# nrf9120_modem register map
Vendor: Nordic Semiconductor; Series: nrf91; File version: 1
CPU: CM4 r0p1, little endian, MPU, FPU, 3 interrupt priority bits
Registers are 32-bit, read-write, reset 0x0 unless marked. A register's access mark holds for its fields unless they carry their own. Offsets are from the block's base; [hi:lo] are bit positions; 'fields as' and 'values as' point back to an identical list.

## TLSAES_NS — AES cipher with ECB, CBC, CBC-MAC and CTR
Base 0x40051000
0x00 TASKS_START_GATHER wo — Start input DMA
  [0] TASKS_START_GATHER
    1=Trigger task
0x04 TASKS_STOP_GATHER wo — Stop input DMA
  [0] TASKS_STOP_GATHER
    1=Trigger task
0x08 TASKS_START_SCATTER wo — Start output DMA
  [0] TASKS_START_SCATTER
    1=Trigger task
0x0C TASKS_STOP_SCATTER wo — Stop output DMA
  [0] TASKS_STOP_SCATTER
    1=Trigger task
0x10 TASKS_INITIALIZE_AES wo — New keys (and IV) ready to be used, reset keybytes, ivbytes
  [0] TASKS_INITIALIZE_AES
    1=Trigger task
0x14 TASKS_FILL_AES_INPUT wo — Transfer 8 bytes of input from DMA to AES core
  [0] TASKS_FILL_AES_INPUT
    1=Trigger task
0x18 TASKS_AES_ENCRYPT wo — Encrypt
  [0] TASKS_AES_ENCRYPT
    1=Trigger task
0x1C TASKS_AES_DECRYPT wo — Decrypt
  [0] TASKS_AES_DECRYPT
    1=Trigger task
0x20 TASKS_DRAIN_AES_OUTPUT wo — Transfer 8 bytes of output from AES core to DMA
  [0] TASKS_DRAIN_AES_OUTPUT
    1=Trigger task
0x24 TASKS_RESET wo — Stop all transfers and crypto operations (software reset)
  [0] TASKS_RESET
    1=Trigger task
0x100 EVENTS_GATHER_STARTED — Input DMA started
  [0] EVENTS_GATHER_STARTED
    0=NotGenerated (Event not generated); 1=Generated (Event generated)
0x104 EVENTS_GATHER_DONE — Input DMA done
  [0] EVENTS_GATHER_DONE
    values as EVENTS_GATHER_STARTED.EVENTS_GATHER_STARTED
0x108 EVENTS_SCATTER_STARTED — Output DMA started
  [0] EVENTS_SCATTER_STARTED
    values as EVENTS_GATHER_STARTED.EVENTS_GATHER_STARTED
0x10C EVENTS_SCATTER_DONE — Output DMA done
  [0] EVENTS_SCATTER_DONE
    values as EVENTS_GATHER_STARTED.EVENTS_GATHER_STARTED
0x110 EVENTS_KEY_READY — Key received (keybytes == 16)
  [0] EVENTS_KEY_READY
    values as EVENTS_GATHER_STARTED.EVENTS_GATHER_STARTED
0x114 EVENTS_IV_READY — IV received (ivbytes == 16)
  [0] EVENTS_IV_READY
    values as EVENTS_GATHER_STARTED.EVENTS_GATHER_STARTED
0x118 EVENTS_AES_INITIALIZED — New keys (and IV) taken into use
  [0] EVENTS_AES_INITIALIZED
    values as EVENTS_GATHER_STARTED.EVENTS_GATHER_STARTED
0x11C EVENTS_AES_INPUT_FULL — 8 bytes of input stored to AES core
  [0] EVENTS_AES_INPUT_FULL
    values as EVENTS_GATHER_STARTED.EVENTS_GATHER_STARTED
0x120 EVENTS_AES_DONE — Encrypt/decrypt action ready
  [0] EVENTS_AES_DONE
    values as EVENTS_GATHER_STARTED.EVENTS_GATHER_STARTED
0x124 EVENTS_AES_OUTPUT_EMPTY — 8 bytes of output read from AES core
  [0] EVENTS_AES_OUTPUT_EMPTY
    values as EVENTS_GATHER_STARTED.EVENTS_GATHER_STARTED
0x128 EVENTS_MAC_READY — CBC-MAC calculated
  [0] EVENTS_MAC_READY
    values as EVENTS_GATHER_STARTED.EVENTS_GATHER_STARTED
0x12C EVENTS_RESETTED — Resetted (all transfers and crypto operations stopped)
  [0] EVENTS_RESETTED
    values as EVENTS_GATHER_STARTED.EVENTS_GATHER_STARTED
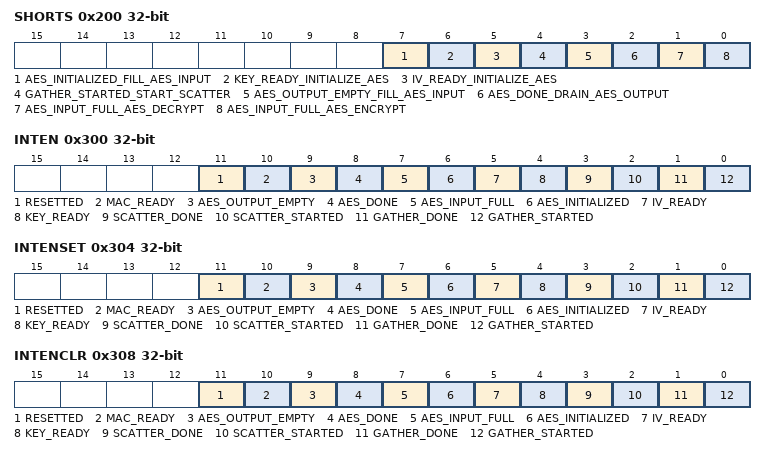
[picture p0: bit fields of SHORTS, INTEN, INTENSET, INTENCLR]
0x200 SHORTS — Shortcuts between local events and tasks
  [all] fields
    0=Disabled (Disable shortcut); 1=Enabled (Enable shortcut)
  [7] AES_INITIALIZED_FILL_AES_INPUT — Shortcut between event AES_INITIALIZED and task FILL_AES_INPUT
  [6] KEY_READY_INITIALIZE_AES — Shortcut between event KEY_READY and task INITIALIZE_AES
  [5] IV_READY_INITIALIZE_AES — Shortcut between event IV_READY and task INITIALIZE_AES
  [4] GATHER_STARTED_START_SCATTER — Shortcut between event GATHER_STARTED and task START_SCATTER
  [3] AES_OUTPUT_EMPTY_FILL_AES_INPUT — Shortcut between event AES_OUTPUT_EMPTY and task FILL_AES_INPUT
  [2] AES_DONE_DRAIN_AES_OUTPUT — Shortcut between event AES_DONE and task DRAIN_AES_OUTPUT
  [1] AES_INPUT_FULL_AES_DECRYPT — Shortcut between event AES_INPUT_FULL and task AES_DECRYPT
  [0] AES_INPUT_FULL_AES_ENCRYPT — Shortcut between event AES_INPUT_FULL and task AES_ENCRYPT
0x300 INTEN — Enable or disable interrupt
  [all] fields
    0=Disabled; 1=Enabled
  [11] RESETTED — Enable or disable interrupt for event RESETTED
  [10] MAC_READY — Enable or disable interrupt for event MAC_READY
  [9] AES_OUTPUT_EMPTY — Enable or disable interrupt for event AES_OUTPUT_EMPTY
  [8] AES_DONE — Enable or disable interrupt for event AES_DONE
  [7] AES_INPUT_FULL — Enable or disable interrupt for event AES_INPUT_FULL
  [6] AES_INITIALIZED — Enable or disable interrupt for event AES_INITIALIZED
  [5] IV_READY — Enable or disable interrupt for event IV_READY
  [4] KEY_READY — Enable or disable interrupt for event KEY_READY
  [3] SCATTER_DONE — Enable or disable interrupt for event SCATTER_DONE
  [2] SCATTER_STARTED — Enable or disable interrupt for event SCATTER_STARTED
  [1] GATHER_DONE — Enable or disable interrupt for event GATHER_DONE
  [0] GATHER_STARTED — Enable or disable interrupt for event GATHER_STARTED
0x304 INTENSET — Enable interrupt
  [all] fields
    on read: 0=Disabled (Read: Disabled); 1=Enabled (Read: Enabled) | on write: 1=Set (Enable)
  [11] RESETTED — Write '1' to enable interrupt for event RESETTED
  [10] MAC_READY — Write '1' to enable interrupt for event MAC_READY
  [9] AES_OUTPUT_EMPTY — Write '1' to enable interrupt for event AES_OUTPUT_EMPTY
  [8] AES_DONE — Write '1' to enable interrupt for event AES_DONE
  [7] AES_INPUT_FULL — Write '1' to enable interrupt for event AES_INPUT_FULL
  [6] AES_INITIALIZED — Write '1' to enable interrupt for event AES_INITIALIZED
  [5] IV_READY — Write '1' to enable interrupt for event IV_READY
  [4] KEY_READY — Write '1' to enable interrupt for event KEY_READY
  [3] SCATTER_DONE — Write '1' to enable interrupt for event SCATTER_DONE
  [2] SCATTER_STARTED — Write '1' to enable interrupt for event SCATTER_STARTED
  [1] GATHER_DONE — Write '1' to enable interrupt for event GATHER_DONE
  [0] GATHER_STARTED — Write '1' to enable interrupt for event GATHER_STARTED
0x308 INTENCLR — Disable interrupt
  [all] fields
    on read: 0=Disabled (Read: Disabled); 1=Enabled (Read: Enabled) | on write: 1=Clear (Disable)
  [11] RESETTED — Write '1' to disable interrupt for event RESETTED
  [10] MAC_READY — Write '1' to disable interrupt for event MAC_READY
  [9] AES_OUTPUT_EMPTY — Write '1' to disable interrupt for event AES_OUTPUT_EMPTY
  [8] AES_DONE — Write '1' to disable interrupt for event AES_DONE
  [7] AES_INPUT_FULL — Write '1' to disable interrupt for event AES_INPUT_FULL
  [6] AES_INITIALIZED — Write '1' to disable interrupt for event AES_INITIALIZED
  [5] IV_READY — Write '1' to disable interrupt for event IV_READY
  [4] KEY_READY — Write '1' to disable interrupt for event KEY_READY
  [3] SCATTER_DONE — Write '1' to disable interrupt for event SCATTER_DONE
  [2] SCATTER_STARTED — Write '1' to disable interrupt for event SCATTER_STARTED
  [1] GATHER_DONE — Write '1' to disable interrupt for event GATHER_DONE
  [0] GATHER_STARTED — Write '1' to disable interrupt for event GATHER_STARTED
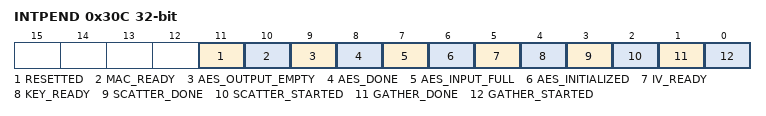
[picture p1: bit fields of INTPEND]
0x30C INTPEND ro — Pending interrupts
  [all] fields
    on read: 0=NotPending (Read: Not pending); 1=Pending (Read: Pending)
  [11] RESETTED — Read pending status of interrupt for event RESETTED
  [10] MAC_READY — Read pending status of interrupt for event MAC_READY
  [9] AES_OUTPUT_EMPTY — Read pending status of interrupt for event AES_OUTPUT_EMPTY
  [8] AES_DONE — Read pending status of interrupt for event AES_DONE
  [7] AES_INPUT_FULL — Read pending status of interrupt for event AES_INPUT_FULL
  [6] AES_INITIALIZED — Read pending status of interrupt for event AES_INITIALIZED
  [5] IV_READY — Read pending status of interrupt for event IV_READY
  [4] KEY_READY — Read pending status of interrupt for event KEY_READY
  [3] SCATTER_DONE — Read pending status of interrupt for event SCATTER_DONE
  [2] SCATTER_STARTED — Read pending status of interrupt for event SCATTER_STARTED
  [1] GATHER_DONE — Read pending status of interrupt for event GATHER_DONE
  [0] GATHER_STARTED — Read pending status of interrupt for event GATHER_STARTED
0x400 MODE — Operation mode
  [1:0] MODE — Selects ECB, CBC, CBC-MAC or CTR mode
    0=ECB (Electronic Codebook mode); 1=CBC (Cipher Block Chaining mode); 2=CBCMAC (Cipher Block Chaining Message Authentication Code mode); 3=CTR (Counter mode)
0x404 CTRBITS — Amount of counter bits used in the CTR mode
  [6:0] CTRBITS
0x408 KEYMODE — Selects which key is utilized in ciphering operations
  [1:0] KEYMODE — Keying mode
    0=Nonsecure (Use a non-secure key received via DMA); 1=Secure (Use a secure key from the specific secure key register); 2=KPRTL (Use the K-PRTL key)
0x40C LENGTH — Length of the CBC-MAC data to be authenticated
  [23:0] LENGTH
0x500 ENABLE — Enable/disable block
  [0] ENABLE — Enable or disable AES module
    0=Disabled; 1=Enabled
0x800 INJOBPTR — Pointer to the memory address containing the input job list
  [31:0] INJOBPTR — Input job pointer
0x900 OUTJOBPTR — Pointer to the memory address containing the output job list
  [31:0] OUTJOBPTR — Output job pointer
